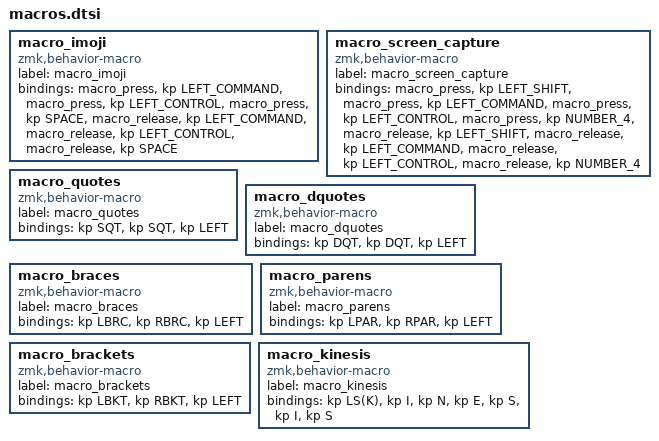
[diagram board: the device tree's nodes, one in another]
macro_imoji: macro_imoji{
compatible = "zmk,behavior-macro";
label = "macro_imoji";
#binding-cells = <0>;
bindings = <&macro_press &kp LEFT_COMMAND>, <&macro_press &kp LEFT_CONTROL>, <&macro_press &kp SPACE>, <&macro_release &kp LEFT_COMMAND>, <&macro_release &kp LEFT_CONTROL>, <&macro_release &kp SPACE>;
};
macro_screen_capture: macro_screen_capture{
compatible = "zmk,behavior-macro";
label = "macro_screen_capture";
#binding-cells = <0>;
bindings = <&macro_press &kp LEFT_SHIFT>, <&macro_press &kp LEFT_COMMAND>, <&macro_press &kp LEFT_CONTROL>, <&macro_press &kp NUMBER_4>, <&macro_release &kp LEFT_SHIFT>, <&macro_release &kp LEFT_COMMAND>, <&macro_release &kp LEFT_CONTROL>, <&macro_release &kp NUMBER_4>;
};
macro_quotes: macro_quotes{
compatible = "zmk,behavior-macro";
label = "macro_quotes";
#binding-cells = <0>;
bindings = <&kp SQT>, <&kp SQT>, <&kp LEFT>;
};
macro_dquotes: macro_dquotes{
compatible = "zmk,behavior-macro";
label = "macro_dquotes";
#binding-cells = <0>;
bindings = <&kp DQT>, <&kp DQT>, <&kp LEFT>;
};
macro_braces: macro_braces{
compatible = "zmk,behavior-macro";
label = "macro_braces";
#binding-cells = <0>;
bindings = <&kp LBRC>, <&kp RBRC>, <&kp LEFT>;
};
macro_parens: macro_parens{
compatible = "zmk,behavior-macro";
label = "macro_parens";
#binding-cells = <0>;
bindings = <&kp LPAR>, <&kp RPAR>, <&kp LEFT>;
};
macro_brackets: macro_brackets{
compatible = "zmk,behavior-macro";
label = "macro_brackets";
#binding-cells = <0>;
bindings = <&kp LBKT>, <&kp RBKT>, <&kp LEFT>;
};
macro_kinesis: macro_kinesis{
compatible = "zmk,behavior-macro";
label = "macro_kinesis";
#binding-cells = <0>;
bindings = <&kp LS(K)>, <&kp I>, <&kp N>, <&kp E>, <&kp S>, <&kp I>, <&kp S>;
};
